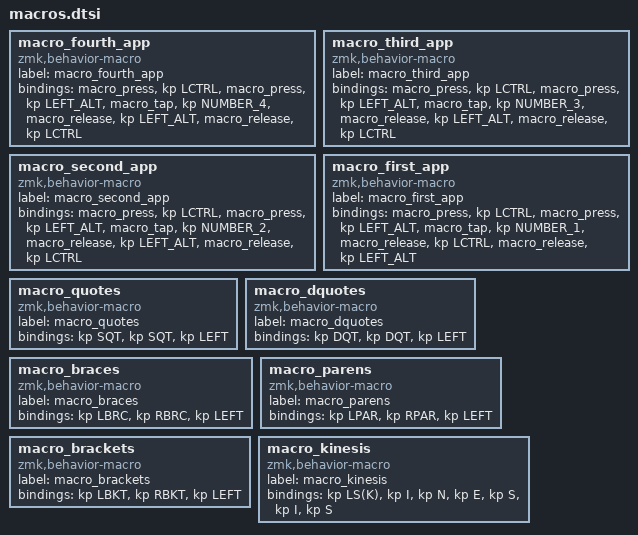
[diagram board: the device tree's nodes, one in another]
macro_fourth_app: macro_fourth_app{
compatible = "zmk,behavior-macro";
label = "macro_fourth_app";
#binding-cells = <0>;
bindings
        = <&macro_press &kp LCTRL>
        , <&macro_press &kp LEFT_ALT>
        , <&macro_tap &kp NUMBER_4>
        , <&macro_release &kp LEFT_ALT>
        , <&macro_release &kp LCTRL>
        ;
};
macro_third_app: macro_third_app{
compatible = "zmk,behavior-macro";
label = "macro_third_app";
#binding-cells = <0>;
bindings
        = <&macro_press &kp LCTRL>
        , <&macro_press &kp LEFT_ALT>
        , <&macro_tap &kp NUMBER_3>
        , <&macro_release &kp LEFT_ALT>
        , <&macro_release &kp LCTRL>
        ;
};
macro_second_app: macro_second_app{
compatible = "zmk,behavior-macro";
label = "macro_second_app";
#binding-cells = <0>;
bindings
        = <&macro_press &kp LCTRL>
        , <&macro_press &kp LEFT_ALT>
        , <&macro_tap &kp NUMBER_2>
        , <&macro_release &kp LEFT_ALT>
        , <&macro_release &kp LCTRL>
        ;
};
macro_first_app: macro_first_app{
compatible = "zmk,behavior-macro";
label = "macro_first_app";
#binding-cells = <0>;
bindings
        = <&macro_press &kp LCTRL>
        , <&macro_press &kp LEFT_ALT>
        , <&macro_tap &kp NUMBER_1>
        , <&macro_release &kp LCTRL>
        , <&macro_release &kp LEFT_ALT>
        ;
};
macro_quotes: macro_quotes{
compatible = "zmk,behavior-macro";
label = "macro_quotes";
#binding-cells = <0>;
bindings = <&kp SQT>, <&kp SQT>, <&kp LEFT>;
};
macro_dquotes: macro_dquotes{
compatible = "zmk,behavior-macro";
label = "macro_dquotes";
#binding-cells = <0>;
bindings = <&kp DQT>, <&kp DQT>, <&kp LEFT>;
};
macro_braces: macro_braces{
compatible = "zmk,behavior-macro";
label = "macro_braces";
#binding-cells = <0>;
bindings = <&kp LBRC>, <&kp RBRC>, <&kp LEFT>;
};
macro_parens: macro_parens{
compatible = "zmk,behavior-macro";
label = "macro_parens";
#binding-cells = <0>;
bindings = <&kp LPAR>, <&kp RPAR>, <&kp LEFT>;
};
macro_brackets: macro_brackets{
compatible = "zmk,behavior-macro";
label = "macro_brackets";
#binding-cells = <0>;
bindings = <&kp LBKT>, <&kp RBKT>, <&kp LEFT>;
};
macro_kinesis: macro_kinesis{
compatible = "zmk,behavior-macro";
label = "macro_kinesis";
#binding-cells = <0>;
bindings = <&kp LS(K)>, <&kp I>, <&kp N>, <&kp E>, <&kp S>, <&kp I>, <&kp S>;
};
